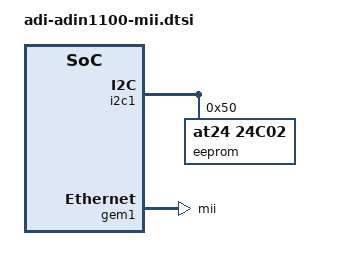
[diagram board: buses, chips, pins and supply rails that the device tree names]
&i2c1 {
	i2c-mux@75 {
		i2c@1 {
			#address-cells = <1>;
			#size-cells = <0>;
			reg = <1>;
			/* HPC1_IIC */
			eeprom@50 {
				compatible = "at24,24c02";
				reg = <0x50>;
			};
		};
	};
};

&gem1 {
	status = "okay";
	phy-mode = "mii";
};
